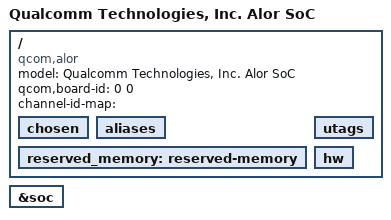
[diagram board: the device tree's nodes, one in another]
// SPDX-License-Identifier: BSD-3-Clause
/*
 * Copyright (c) 2025 Qualcomm Innovation Center, Inc. All rights reserved.
 */

/dts-v1/;

#include "alor.dtsi"

/ {
	model = "Qualcomm Technologies, Inc. Alor SoC";
	compatible = "qcom,alor";
	qcom,board-id = <0 0>;
/*
 * Moto common base dtb nodes definition
 */
	channel-id-map = "";
	chosen: chosen { };
	aliases: aliases { };
	reserved_memory: reserved-memory { };
	utags: utags { };
	hw: hw { };
};

&reserved_memory {
	/delete-node/ ramoops-region;
};

&soc {
	/delete-node/ qcom_ramoops;
};
